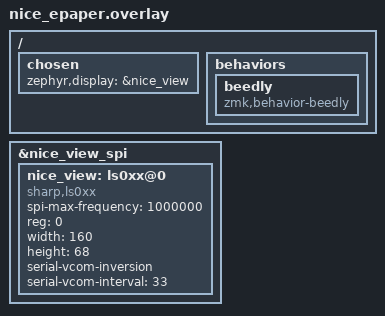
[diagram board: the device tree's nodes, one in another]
/*
 * Copyright (c) 2022 The ZMK Contributors
 *
 * SPDX-License-Identifier: MIT
 */

&nice_view_spi {
    status = "okay";
    nice_view: ls0xx@0 {
        compatible = "sharp,ls0xx";
        spi-max-frequency = <1000000>;
        reg = <0>;
        width = <160>;
        height = <68>;
        serial-vcom-inversion;
        serial-vcom-interval = <33>;
    };
};

/ {
    chosen {
        zephyr,display = &nice_view;
    };

    /*
     * Beedly pet (see include/dt-bindings/zmk/beedly.h). Declared here, in the shield overlay
     * both halves build, because the central sends BEEDLY_PET/FEED/SAVE to the peripheral by
     * this node's device name ("beedly") and the peripheral looks it up by that name. A keymap's
     * own `behaviors` node merges with this one; it only must not reuse the `beedly` label.
     */
    behaviors {
        beedly: beedly {
            compatible = "zmk,behavior-beedly";
            #binding-cells = <1>;
        };
    };
};
